AUTOSAR XML (schema 00044)
package /VehicleProject
  system System
    system mapping System_MPPNG
      data-mappings:
        data-element=If_HIL_Vx.Cnt, system-signal=Cnt
        data-element=If_HIL_Vx.Vx, system-signal=Vx
        data-element=If_HIL_Cmd.Fault, system-signal=Fault
        data-element=If_HIL_Cmd.Heartbeat, system-signal=Heartbeat
        data-element=If_HIL_Cmd.Pcon, system-signal=Pcon
        data-element=If_HIL_Cmd.Throttle, system-signal=Throttle
    root-software-compositions:
      root sw composition prototype EcuSwComposition: software-composition=ECU_Composition
package /ECUCompositionTypes
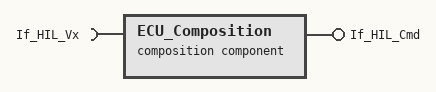
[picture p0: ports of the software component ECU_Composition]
  composition sw component type ECU_Composition
    require port If_HIL_Vx: required-interface=If_HIL_Vx
    provide port If_HIL_Cmd: provided-interface=If_HIL_Cmd
    component HIL_Controller: type=HIL_Controller
    delegate HIL_Controller.R_HIL_Vx <-> outer port If_HIL_Vx
    delegate HIL_Controller.P_HIL_Cmd <-> outer port If_HIL_Cmd
package /EndToEndProtections
  end to end protection set EndToEndProtectionSet
